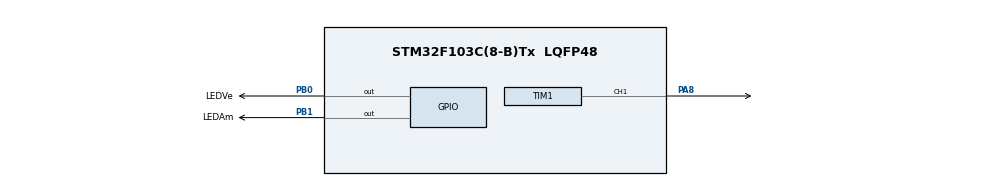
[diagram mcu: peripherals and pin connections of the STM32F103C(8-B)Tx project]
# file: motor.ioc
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Mcu.Family=STM32F1
Mcu.Name=STM32F103C(8-B)Tx
Mcu.Package=LQFP48
NVIC.PriorityGroup=NVIC_PRIORITYGROUP_4
PA8.Signal=S_TIM1_CH1
PB0.GPIO_Label=LEDVe
PB0.Signal=GPIO_Output
PB1.GPIO_Label=LEDAm
PB1.Signal=GPIO_Output
ProjectManager.HeapSize=0x200
ProjectManager.StackSize=0x400
ProjectManager.TargetToolchain=STM32CubeIDE
RCC.AHBFreq_Value=8000000
RCC.APB1Freq_Value=8000000
RCC.APB1TimFreq_Value=8000000
RCC.APB2Freq_Value=8000000
RCC.APB2TimFreq_Value=8000000
RCC.HCLKFreq_Value=8000000
SH.S_TIM1_CH1.0=TIM1_CH1,PWM Generation1 CH1
TIM1.Channel-PWM\ Generation1\ CH1=TIM_CHANNEL_1
TIM1.Period=20000
TIM1.Prescaler=7
VP_SYS_VS_ND.Mode=No_Debug
board=custom

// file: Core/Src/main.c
/* USER CODE BEGIN Header */
/**
  ******************************************************************************
  * @file           : main.c
  * @brief          : Main program body
  ******************************************************************************
  * @attention
  *
  * Copyright (c) 2025 STMicroelectronics.
  * All rights reserved.
  *
  * This software is licensed under terms that can be found in the LICENSE file
  * in the root directory of this software component.
  * If no LICENSE file comes with this software, it is provided AS-IS.
  *
  ******************************************************************************
  */
/* USER CODE END Header */
#include "main.h"
#include "tim.h"
#include "gpio.h"

/* USER CODE BEGIN Includes */
#include "dronMotor.h"
/* USER CODE END Includes */

void SystemClock_Config(void);

int main(void)
{
  /* Reset of all peripherals, Initializes the Flash interface and the Systick. */
  HAL_Init();

  /* Configure the system clock */
  SystemClock_Config();

  /* Initialize all configured peripherals */
  MX_GPIO_Init();
  MX_TIM1_Init();

  HAL_TIM_PWM_Start(&htim1, TIM_CHANNEL_1);
  HAL_GPIO_WritePin(LEDAm_GPIO_Port, LEDAm_Pin, GPIO_PIN_SET);

  dronMotor_Init();

  while (1)
  {
	  dronMotor_Update();
  }

}

void SystemClock_Config(void)
{
  RCC_OscInitTypeDef RCC_OscInitStruct = {0};
  RCC_ClkInitTypeDef RCC_ClkInitStruct = {0};

  /** Initializes the RCC Oscillators according to the specified parameters
  * in the RCC_OscInitTypeDef structure.
  */
  RCC_OscInitStruct.OscillatorType = RCC_OSCILLATORTYPE_HSI;
  RCC_OscInitStruct.HSIState = RCC_HSI_ON;
  RCC_OscInitStruct.HSICalibrationValue = RCC_HSICALIBRATION_DEFAULT;
  RCC_OscInitStruct.PLL.PLLState = RCC_PLL_NONE;
  if (HAL_RCC_OscConfig(&RCC_OscInitStruct) != HAL_OK)
  {
    Error_Handler();
  }

  /** Initializes the CPU, AHB and APB buses clocks
  */
  RCC_ClkInitStruct.ClockType = RCC_CLOCKTYPE_HCLK|RCC_CLOCKTYPE_SYSCLK
                              |RCC_CLOCKTYPE_PCLK1|RCC_CLOCKTYPE_PCLK2;
  RCC_ClkInitStruct.SYSCLKSource = RCC_SYSCLKSOURCE_HSI;
  RCC_ClkInitStruct.AHBCLKDivider = RCC_SYSCLK_DIV1;
  RCC_ClkInitStruct.APB1CLKDivider = RCC_HCLK_DIV1;
  RCC_ClkInitStruct.APB2CLKDivider = RCC_HCLK_DIV1;

  if (HAL_RCC_ClockConfig(&RCC_ClkInitStruct, FLASH_LATENCY_0) != HAL_OK)
  {
    Error_Handler();
  }
}

void Error_Handler(void)
{
  __disable_irq();
  while (1)
  {
  }
}
